# STM32F091xC register map
File version: 1.0
Registers are 32-bit, read-write, reset 0x0 unless marked. A register's access mark holds for its fields unless they carry their own. Offsets are from the block's base; [hi:lo] are bit positions; {n}, {i} and the like mark numbered series; 'fields as' and 'values as' point back to an identical list.

## SYSCFG — SysTem Configuration
Base 0x40010000
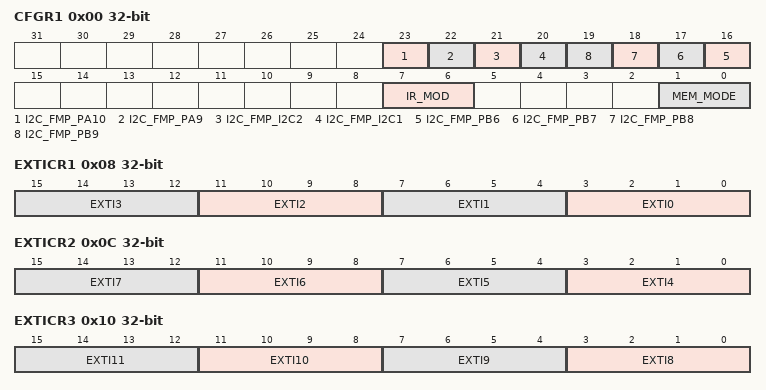
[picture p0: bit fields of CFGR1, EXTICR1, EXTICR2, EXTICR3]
0x00 CFGR1 — SYSCFG configuration register 1
  [23] I2C_FMP_PA10 — Enable Fast Mode Plus on PA10
  [22] I2C_FMP_PA9 — Enable Fast Mode Plus on PA9
  [21] I2C_FMP_I2C2 — Enable I2C2 Fast mode plus
  [20] I2C_FMP_I2C1 — Enable Fast Mode Plus on PB10, PB11, PF6 and PF7
  [n+10] I2C_FMP_PB{n} (n=6..9) — I2C PB{n} Fast mode plus
  [7:6] IR_MOD — IR_MOD config
    0=TIM16 (Timer16 is selected as IR Modulation envelope source); 1=USART1 (USART1 is selected as IR Modulation envelope source); 2=USART4 (USART4 is selected as IR Modulation envelope source)
  [1:0] MEM_MODE — SYSCFG_Memory Remap Config
    0=FLASH (Main Flash memory mapped at 0x00000000); 1=SYSTEMFLASH (System Flash memory mapped at 0x00000000); 3=SRAM (Embedded SRAM mapped at 0x00000000)
0x08 EXTICR1 — SYSCFG external interrupt configuration register
  [4n+3:4n] EXTI{n} (n=0..3) — EXTI {n} configuration
0x0C EXTICR2 — SYSCFG external interrupt configuration register
  [4n-13:4n-16] EXTI{n} (n=4..7) — EXTI {n} configuration
0x10 EXTICR3 — SYSCFG external interrupt configuration register
  [4n-29:4n-32] EXTI{n} (n=8..11) — EXTI {n} configuration
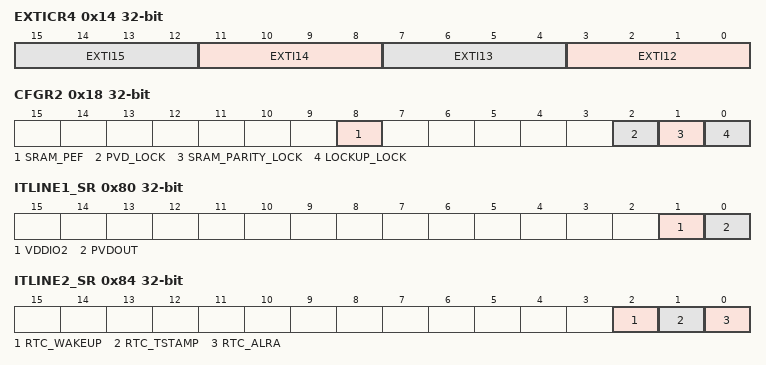
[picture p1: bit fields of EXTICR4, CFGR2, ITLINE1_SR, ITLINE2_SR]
0x14 EXTICR4 — SYSCFG external interrupt configuration register
  [4n-45:4n-48] EXTI{n} (n=12..15) — EXTI {n} configuration
0x18 CFGR2 — SYSCFG configuration register 2
  [8] SRAM_PEF — SRAM Parity error flag
  [2] PVD_LOCK — Enables and locks the PVD connection with Timer1 Break Input and also the PVD_EN and PVDSEL[2:0] bits of the Power Control Interface
  [1] SRAM_PARITY_LOCK — Enables and locks the SRAM_PARITY error signal with Break Input of TIMER1
  [0] LOCKUP_LOCK — Enables and locks the LOCKUP (Hardfault) output of CortexM0 with Break Input of TIMER1
0x80 ITLINE1_SR — SYSCFG configuration IT_LINE register
  [1] VDDIO2 — VDDIO2 -> exti[16] Interrupt
  [0] PVDOUT — Power voltage detection -> exti[31] Interrupt
0x84 ITLINE2_SR — SYSCFG configuration IT_LINE register
  [2] RTC_WAKEUP — RTC WAKEUP -> exti[20] Interrupt
  [1] RTC_TSTAMP — RTC Time Stamp -> exti[19] interrupt
  [0] RTC_ALRA — RTC Alarm -> exti[17] interrupt
0x88 ITLINE3_SR — SYSCFG configuration IT_LINE register
  [0] FLASH_ITF — Flash ITF Interrupt
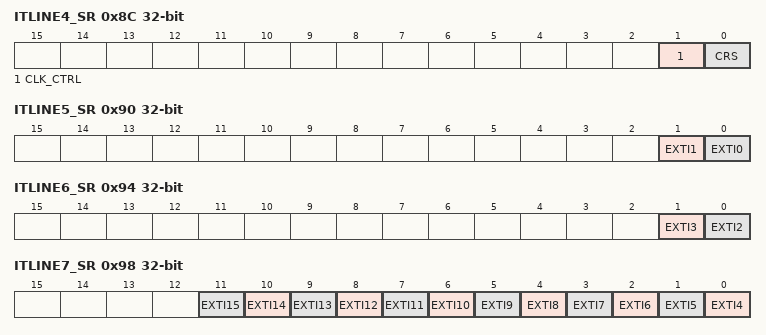
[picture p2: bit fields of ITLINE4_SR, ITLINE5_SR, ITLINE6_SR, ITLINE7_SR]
0x8C ITLINE4_SR — SYSCFG configuration IT_LINE register
  [1] CLK_CTRL — CLK CTRL interrupt
  [0] CRS — CRS interrupt
0x90 ITLINE5_SR — SYSCFG configuration IT_LINE register
  [1] EXTI1 — External Interrupt 1
  [0] EXTI0 — External Interrupt 0
0x94 ITLINE6_SR — SYSCFG configuration IT_LINE register
  [1] EXTI3 — External Interrupt 3
  [0] EXTI2 — External Interrupt 2
0x98 ITLINE7_SR — SYSCFG configuration IT_LINE register
  [n-4] EXTI{n} (n=4..15) — External Interrupt 15 to 4
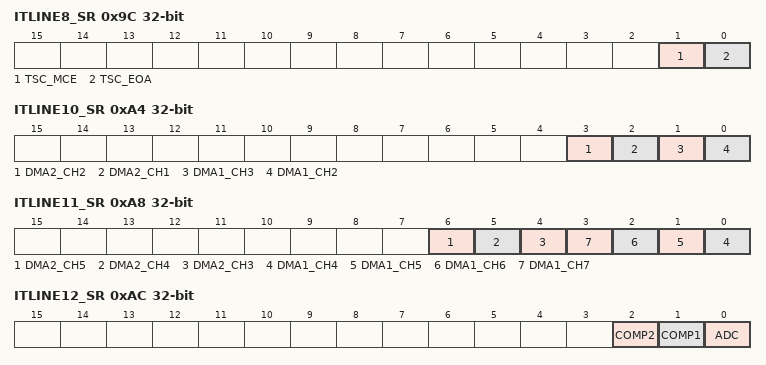
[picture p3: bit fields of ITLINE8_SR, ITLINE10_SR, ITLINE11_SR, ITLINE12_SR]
0x9C ITLINE8_SR — SYSCFG configuration IT_LINE register
  [1] TSC_MCE — Touch control MCE Interrupt
  [0] TSC_EOA — Touch control EOA Interrupt
0xA0 ITLINE9_SR — SYSCFG configuration IT_LINE register
  [0] DMA1_CH1 — DMA1 Channel 1 Interrupt
0xA4 ITLINE10_SR — SYSCFG configuration IT_LINE register
  [3] DMA2_CH2 — DMA2 Channel 2 Interrupt
  [2] DMA2_CH1 — DMA2 Channel 1 Interrupt
  [1] DMA1_CH3 — DMA2 Channel 3 Interrupt
  [0] DMA1_CH2 — DMA1 Channel 2 Interrupt
0xA8 ITLINE11_SR — SYSCFG configuration IT_LINE register
  [6] DMA2_CH5 — DMA2 Channel 5 Interrupt
  [5] DMA2_CH4 — DMA2 Channel 4 Interrupt
  [4] DMA2_CH3 — DMA2 Channel 3 Interrupt
  [n-4] DMA1_CH{n} (n=4..7) — DMA1 Channel {n} Interrupt
0xAC ITLINE12_SR — SYSCFG configuration IT_LINE register
  [2] COMP2 — COMP2 Interrupt -> exti[22]
  [1] COMP1 — COMP1 Interrupt -> exti[21]
  [0] ADC — ADC Interrupt
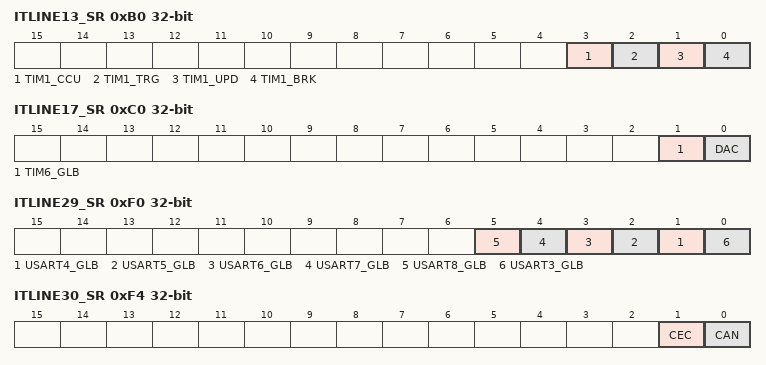
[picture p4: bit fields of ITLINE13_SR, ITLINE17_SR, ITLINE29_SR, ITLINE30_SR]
0xB0 ITLINE13_SR — SYSCFG configuration IT_LINE register
  [3] TIM1_CCU — TIM1 CCU Interrupt
  [2] TIM1_TRG — TIM1 TRG Interrupt
  [1] TIM1_UPD — TIM1 UPD Interrupt
  [0] TIM1_BRK — TIM1 BRK Interrupt
0xB4 ITLINE14_SR — SYSCFG configuration IT_LINE register
  [0] TIM1_CC — TIM1 CC Interrupt
0xB8 ITLINE15_SR — SYSCFG configuration IT_LINE register
  [0] TIM2_GLB — TIM2 GLB Interrupt
0xBC ITLINE16_SR — SYSCFG configuration IT_LINE register
  [0] TIM3_GLB — TIM3 GLB Interrupt
0xC0 ITLINE17_SR — SYSCFG configuration IT_LINE register
  [1] TIM6_GLB — TIM6 GLB Interrupt
  [0] DAC — DAC Interrupt
0xC4 ITLINE18_SR — SYSCFG configuration IT_LINE register
  [0] TIM7_GLB — TIM7 GLB Interrupt
{0x7C+4i} ITLINE{i}_SR (i=19..22) — SYSCFG configuration IT_LINE register
  [0] TIM{i-5}_GLB — TIM{i-5} GLB Interrupt
0xD8 ITLINE23_SR — SYSCFG configuration IT_LINE register
  [0] I2C1_GLB — I2C1 GLB Interrupt -> exti[23]
0xDC ITLINE24_SR — SYSCFG configuration IT_LINE register
  [0] I2C2_GLB — I2C2 GLB Interrupt
0xE0 ITLINE25_SR — SYSCFG configuration IT_LINE register
  [0] SPI1 — SPI1 Interrupt
0xE4 ITLINE26_SR — SYSCFG configuration IT_LINE register
  [0] SPI2 — SPI2 Interrupt
0xE8 ITLINE27_SR — SYSCFG configuration IT_LINE register
  [0] USART1_GLB — USART1 GLB Interrupt -> exti[25]
0xEC ITLINE28_SR — SYSCFG configuration IT_LINE register
  [0] USART2_GLB — USART2 GLB Interrupt -> exti[26]
0xF0 ITLINE29_SR — SYSCFG configuration IT_LINE register
  [n-3] USART{n}_GLB (n=4..8) — USART{n} GLB Interrupt
  [0] USART3_GLB — USART3 GLB Interrupt -> exti[28]
0xF4 ITLINE30_SR — SYSCFG configuration IT_LINE register
  [1] CEC — CEC Interrupt
  [0] CAN — CAN Interrupt
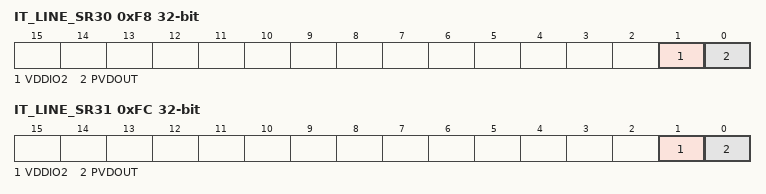
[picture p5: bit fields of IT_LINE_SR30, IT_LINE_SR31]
0xF8 IT_LINE_SR30 — SYSCFG configuration IT_LINE register
  fields as ITLINE1_SR
0xFC IT_LINE_SR31 — SYSCFG configuration IT_LINE register
  fields as ITLINE1_SR
